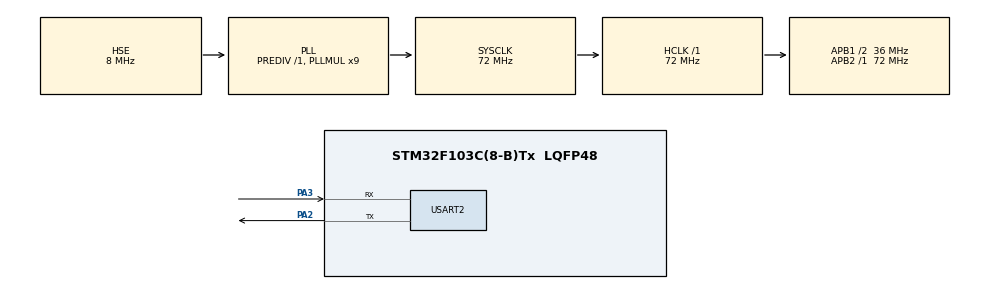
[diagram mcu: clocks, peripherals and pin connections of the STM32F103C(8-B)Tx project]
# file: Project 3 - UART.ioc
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Mcu.Family=STM32F1
Mcu.Name=STM32F103C(8-B)Tx
Mcu.Package=LQFP48
NVIC.PriorityGroup=NVIC_PRIORITYGROUP_4
NVIC.USART2_IRQn=true\:0\:0\:false\:false\:true\:true\:true
PA13.Mode=Serial_Wire
PA13.Signal=SYS_JTMS-SWDIO
PA14.Mode=Serial_Wire
PA14.Signal=SYS_JTCK-SWCLK
PA2.Mode=Asynchronous
PA2.Signal=USART2_TX
PA3.Mode=Asynchronous
PA3.Signal=USART2_RX
PD0-OSC_IN.Mode=HSE-External-Oscillator
PD0-OSC_IN.Signal=RCC_OSC_IN
PD1-OSC_OUT.Mode=HSE-External-Oscillator
PD1-OSC_OUT.Signal=RCC_OSC_OUT
ProjectManager.HeapSize=0x200
ProjectManager.StackSize=0x400
ProjectManager.TargetToolchain=STM32CubeIDE
RCC.AHBFreq_Value=72000000
RCC.APB1CLKDivider=RCC_HCLK_DIV2
RCC.APB1Freq_Value=36000000
RCC.APB1TimFreq_Value=72000000
RCC.APB2Freq_Value=72000000
RCC.APB2TimFreq_Value=72000000
RCC.HCLKFreq_Value=72000000
RCC.PLLMUL=RCC_PLL_MUL9
RCC.PLLSourceVirtual=RCC_PLLSOURCE_HSE
RCC.SYSCLKFreq_VALUE=72000000
RCC.SYSCLKSource=RCC_SYSCLKSOURCE_PLLCLK
RCC.USBFreq_Value=72000000
USART2.VirtualMode=VM_ASYNC
board=custom

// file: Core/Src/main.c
/* USER CODE BEGIN Header */
/**
  ******************************************************************************
  * @file           : main.c
  * @brief          : Main program body
  ******************************************************************************
  * @attention
  *
  * <h2><center>&copy; Copyright (c) 2021 STMicroelectronics.
  * All rights reserved.</center></h2>
  *
  * This software component is licensed by ST under BSD 3-Clause license,
  * the "License"; You may not use this file except in compliance with the
  * License. You may obtain a copy of the License at:
  *                        opensource.org/licenses/BSD-3-Clause
  *
  ******************************************************************************
  */
/* USER CODE END Header */
#include "main.h"

/* USER CODE BEGIN Includes */
#include <sys/types.h>
#include <string.h>
#include "debug.h"
/* USER CODE END Includes */

UART_HandleTypeDef huart2;

void SystemClock_Config(void);
static void MX_GPIO_Init(void);
static void MX_USART2_UART_Init(void);

/* USER CODE BEGIN 0 */
#define BUFFER_SZ 255
#define MAX_TEXT 10

int buf_pos = 0;
uint8_t buffer[BUFFER_SZ] = {0,};

int recv = 0; /* to signal the main loop that we have incoming data from uart. */
uint8_t recv_buf[2] = {0,};

static void help(char **argv, int argc)
{
	char str[] = "Do you need help?";
	output(&huart2, str);
}

static void run(char **argv, int argc)
{
	char str[] = "You want to run something!";
	output(&huart2, str);
}

struct help_text {
	char input[MAX_TEXT];
	void (*func)(char **argv, int argc);
};

struct help_text helper[] = {
		{.input = "help", .func = help },
		{.input = "run", .func = run }
};
int help_sz = sizeof(helper) / sizeof(helper[0]);

static void check_text()
{
	char **argv;
	int argc = 0;
	int ret;

	ret = get_args((char*)buffer, &argv, &argc);
	if(ret || argc < 1) goto end;

	struct help_text *help_text = helper;
	for(int i = 0; i < help_sz; ++i) {
		if(0 == strcmp(argv[0], help_text->input)) {
			help_text->func(argv, argc);
			break;
		}
		++help_text;
	}
	buf_pos = 0;

end:
	free_args(argv, argc);
}
/* USER CODE END 0 */

int main(void)
{

  /* MCU Configuration--------------------------------------------------------*/

  /* Reset of all peripherals, Initializes the Flash interface and the Systick. */
  HAL_Init();

  /* Configure the system clock */
  SystemClock_Config();

  /* Initialize all configured peripherals */
  MX_GPIO_Init();
  MX_USART2_UART_Init();

  /* Infinite loop */
  /* USER CODE BEGIN WHILE */
  HAL_UART_Receive_IT(&huart2, recv_buf, 1);
  while (1)
  {
	  if(recv) {
		  recv = 0;
		  if(recv_buf[0] == '\r' || buf_pos >= BUFFER_SZ) {
			  recv_buf[1] = '\n';
			  HAL_UART_Transmit(&huart2, recv_buf, 2, 500);

			  buffer[buf_pos] = 0;

			  check_text();
			  continue;
		  }

		  buffer[buf_pos++] = recv_buf[0];
		  HAL_UART_Transmit(&huart2, recv_buf, 1, 500);
	  }
    /* USER CODE END WHILE */

  }
}

void SystemClock_Config(void)
{
  RCC_OscInitTypeDef RCC_OscInitStruct = {0};
  RCC_ClkInitTypeDef RCC_ClkInitStruct = {0};

  /** Initializes the RCC Oscillators according to the specified parameters
  * in the RCC_OscInitTypeDef structure.
  */
  RCC_OscInitStruct.OscillatorType = RCC_OSCILLATORTYPE_HSE;
  RCC_OscInitStruct.HSEState = RCC_HSE_ON;
  RCC_OscInitStruct.HSEPredivValue = RCC_HSE_PREDIV_DIV1;
  RCC_OscInitStruct.HSIState = RCC_HSI_ON;
  RCC_OscInitStruct.PLL.PLLState = RCC_PLL_ON;
  RCC_OscInitStruct.PLL.PLLSource = RCC_PLLSOURCE_HSE;
  RCC_OscInitStruct.PLL.PLLMUL = RCC_PLL_MUL9;
  if (HAL_RCC_OscConfig(&RCC_OscInitStruct) != HAL_OK)
  {
    Error_Handler();
  }
  /** Initializes the CPU, AHB and APB buses clocks
  */
  RCC_ClkInitStruct.ClockType = RCC_CLOCKTYPE_HCLK|RCC_CLOCKTYPE_SYSCLK
                              |RCC_CLOCKTYPE_PCLK1|RCC_CLOCKTYPE_PCLK2;
  RCC_ClkInitStruct.SYSCLKSource = RCC_SYSCLKSOURCE_PLLCLK;
  RCC_ClkInitStruct.AHBCLKDivider = RCC_SYSCLK_DIV1;
  RCC_ClkInitStruct.APB1CLKDivider = RCC_HCLK_DIV2;
  RCC_ClkInitStruct.APB2CLKDivider = RCC_HCLK_DIV1;

  if (HAL_RCC_ClockConfig(&RCC_ClkInitStruct, FLASH_LATENCY_2) != HAL_OK)
  {
    Error_Handler();
  }
}

static void MX_USART2_UART_Init(void)
{

  huart2.Instance = USART2;
  huart2.Init.BaudRate = 115200;
  huart2.Init.WordLength = UART_WORDLENGTH_8B;
  huart2.Init.StopBits = UART_STOPBITS_1;
  huart2.Init.Parity = UART_PARITY_NONE;
  huart2.Init.Mode = UART_MODE_TX_RX;
  huart2.Init.HwFlowCtl = UART_HWCONTROL_NONE;
  huart2.Init.OverSampling = UART_OVERSAMPLING_16;
  if (HAL_UART_Init(&huart2) != HAL_OK)
  {
    Error_Handler();
  }

}

static void MX_GPIO_Init(void)
{

  /* GPIO Ports Clock Enable */
  __HAL_RCC_GPIOD_CLK_ENABLE();
  __HAL_RCC_GPIOA_CLK_ENABLE();

}

/* USER CODE BEGIN 4 */
void HAL_UART_RxCpltCallback(UART_HandleTypeDef *huart)
{
	recv = 1;
	HAL_UART_Receive_IT(&huart2, recv_buf, 1);
}

/* USER CODE END 4 */

void Error_Handler(void)
{
  __disable_irq();
  while (1)
  {
  }
}

/************************ (C) COPYRIGHT STMicroelectronics *****END OF FILE****/
